# STM32U366xx register map
File version: 1.0
Registers are 32-bit, read-write, reset 0x0 unless marked. A register's access mark holds for its fields unless they carry their own. Offsets are from the block's base; [hi:lo] are bit positions; {n}, {i} and the like mark numbered series.

## AES — AES hardware accelerator
Base 0x420C0000
Same registers: SAES 0x420C0C00
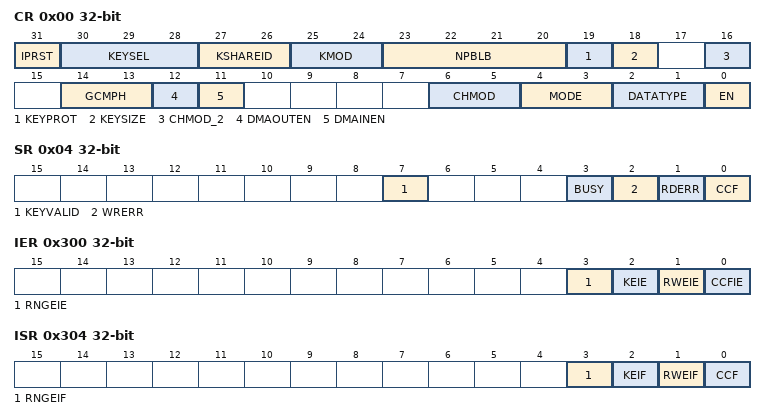
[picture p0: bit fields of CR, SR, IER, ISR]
0x00 CR — AES control register
  [31] IPRST — AES IP software reset
  [30:28] KEYSEL — Key Selection
  [27:26] KSHAREID — Key Shared ID
  [25:24] KMOD — Key mode selection
  [23:20] NPBLB — Number of padding bytes in payload last block
  [19] KEYPROT — Key protection
  [18] KEYSIZE — Key size selection
  [16] CHMOD_2 — AES Chaining Mode
  [14:13] GCMPH — GCM Phase
  [12] DMAOUTEN — Enable data output phase DMA management
  [11] DMAINEN — Enable data input phase DMA management
  [6:5] CHMOD — AES Chaining Mode
  [4:3] MODE — AES Mode Of Operation
  [2:1] DATATYPE — Data type selection
  [0] EN — AES Enable
0x04 SR — AES status register
  [7] KEYVALID — KEYVALID Flag
  [3] BUSY — Busy Flag
  [2] WRERR — Write Error Flag
  [1] RDERR — Read Error Flag
  [0] CCF — Computation Complete Flag
0x08 DINR — AES data input register
  [31:0] DINR — AES Data Input Register
0x0C DOUTR — AES data output register
  [31:0] DOUTR — AES Data Output Register
{0x10+4i} KEYR{i} (i=0..3) — AES key register {i}
  [31:0] KEYR{i} — AES Key Register {i}
{0x20+4i} IVR{i} (i=0..3) — AES initialization vector register {i}
  [31:0] IVR{i} — AES Initialization Vector Register {i}
{0x20+4i} KEYR{i} (i=4..7) — AES key register {i}
  [31:0] KEYR{i} — AES Key Register {i}
{0x40+4i} SUSP{i}R (i=0..7) — AES Suspend register {i}
  [31:0] SUSP{i}R — AES Suspend registers {i}
0x300 IER — AES Interrupt Enable Register
  [3] RNGEIE — Rng error interrupt enable
  [2] KEIE — Key error interrupt enable
  [1] RWEIE — Read or write error Interrupt Enable
  [0] CCFIE — Computation complete flag interrupt enable
0x304 ISR — AES Interrupt Status Register
  [3] RNGEIF — Rng error interrupt flag
  [2] KEIF — Key error interrupt flag
  [1] RWEIF — Read or write error Interrupt flag
  [0] CCF — Computation complete flag
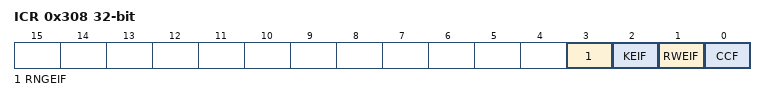
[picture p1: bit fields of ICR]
0x308 ICR — AES Interrupt Clear Register
  [3] RNGEIF — Rng error interrupt flag clear
  [2] KEIF — Key error interrupt flag clear
  [1] RWEIF — Read or write error Interrupt flag clear
  [0] CCF — Computation complete flag clear

## HASH
Base 0x420C0400
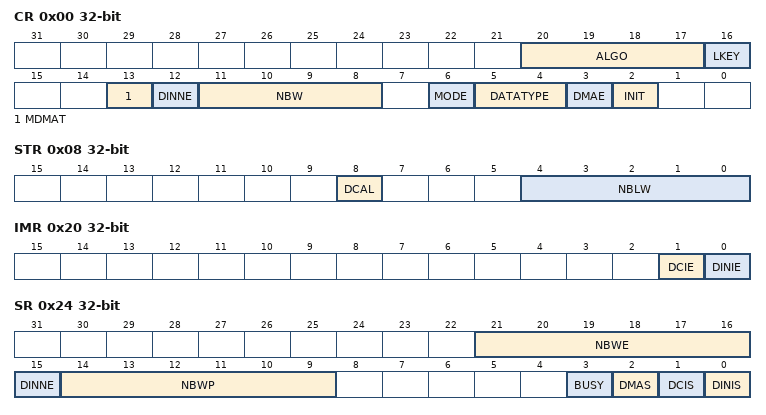
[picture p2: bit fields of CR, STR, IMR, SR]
0x00 CR — HASH control register
  [20:17] ALGO, [16] LKEY, [13] MDMAT, [12] DINNE, [11:8] NBW, [6] MODE, [5:4] DATATYPE, [3] DMAE, [2] INIT
0x04 DIN — HASH data input register
0x08 STR — HASH start register
  [8] DCAL, [4:0] NBLW
{0xC+4i} HR{i} (i=0..4) — HASH digest registers
0x20 IMR — HASH interrupt enable register
  [1] DCIE, [0] DINIE
0x24 SR — HASH status register
  [21:16] NBWE, [15] DINNE, [14:9] NBWP, [3] BUSY, [2] DMAS, [1] DCIS, [0] DINIS
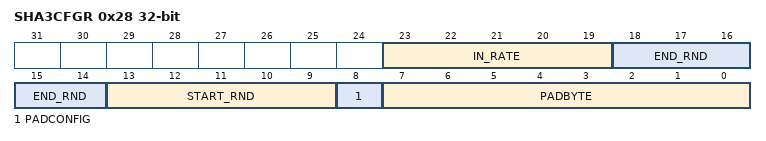
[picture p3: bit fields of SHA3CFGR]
0x28 SHA3CFGR — HASH SHA-3 configuration register
  [23:19] IN_RATE, [18:14] END_RND, [13:9] START_RND, [8] PADCONFIG, [7:0] PADBYTE
{0xF8+4i} CSR[{i}] (i=0..102)
{0x310+4i} DIGEST_HR{i} (i=0..49) — HASH digest registers

## RNG
Base 0x420C0800
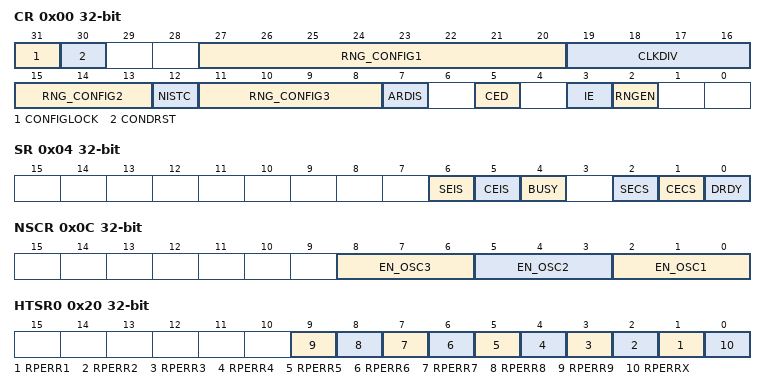
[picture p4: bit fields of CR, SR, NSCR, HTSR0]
0x00 CR — RNG control register
  [31] CONFIGLOCK — RNG configuration lock
  [30] CONDRST — Conditioning soft reset
  [27:20] RNG_CONFIG1 — RNG configuration 1
  [19:16] CLKDIV — Clock divider factor
    0=BY_1 (No clock division); 1=BY_2 (2 RNG clock cycles per internal RNG clock); 2=BY_4 (4 RNG clock cycles per internal RNG clock); 3=BY_8 (8 RNG clock cycles per internal RNG clock); 4=BY_16 (16 RNG clock cycles per internal RNG clock); 5=BY_32 (32 RNG clock cycles per internal RNG clock); 6=BY_64 (64 RNG clock cycles per internal RNG clock); 7=BY_128 (128 RNG clock cycles per internal RNG clock); 8=BY_256 (256 RNG clock cycles per internal RNG clock); 9=BY_512 (512 RNG clock cycles per internal RNG clock); 10=BY_1024 (1024 RNG clock cycles per internal RNG clock); 11=BY_2048 (2048 RNG clock cycles per internal RNG clock); 12=BY_4096 (4096 RNG clock cycles per internal RNG clock); 13=BY_8192 (8192 RNG clock cycles per internal RNG clock); 14=BY_16384 (16384 RNG clock cycles per internal RNG clock); 15=BY_32768 (32768 RNG clock cycles per internal RNG clock)
  [15:13] RNG_CONFIG2 — RNG configuration 2
  [12] NISTC — NIST custom
  [11:8] RNG_CONFIG3 — RNG configuration 3
  [7] ARDIS — Auto reset disable
  [5] CED — Clock error detection
  [3] IE — Interrupt enable
  [2] RNGEN — True random number generator enable
0x04 SR — RNG status register
  [6] SEIS, [5] CEIS, [4] BUSY, [2] SECS, [1] CECS, [0] DRDY
0x08 DR — RNG data register
0x0C NSCR — RNG noise source control register
  [8:6] EN_OSC3, [5:3] EN_OSC2, [2:0] EN_OSC1
{0x10+4i} HTCR{i} (i=0..3) — RNG health test configuration register
  [31:0] HTCFG
0x20 HTSR0 — RNG health test status register
  [n] RPERR{n} (n=1..9) — Repetitive error for oscillator i
  [0] RPERRX — Repetitive error after the XOR
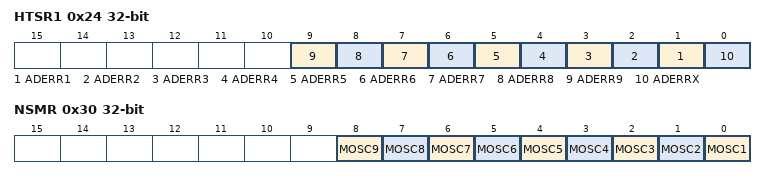
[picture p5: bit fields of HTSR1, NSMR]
0x24 HTSR1 — RNG health test status register
  [n] ADERR{n} (n=1..9) — Adaptative error for oscillator i
  [0] ADERRX — Adaptative error after the XOR
0x30 NSMR — RNG health test status register
  [n-1] MOSC{n} (n=1..9) — Mask oscillator i
